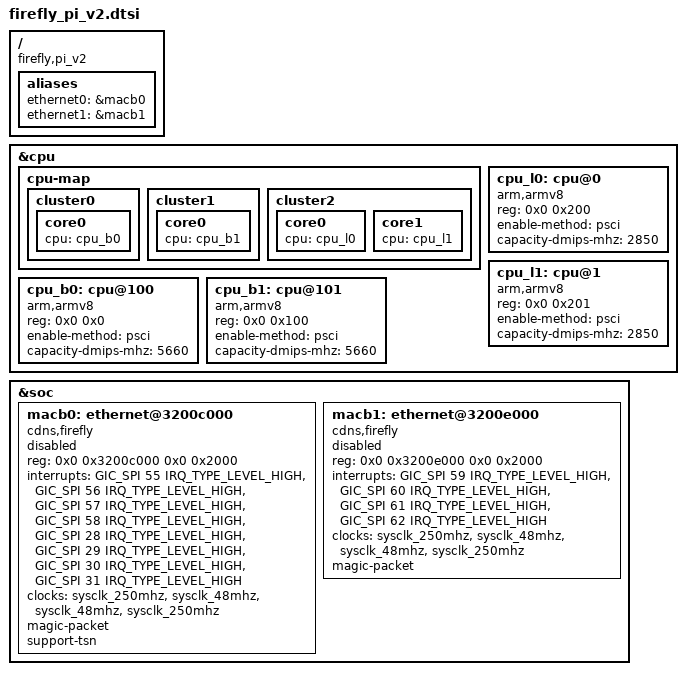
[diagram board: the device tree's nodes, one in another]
#include "firefly_v2.dtsi"

/ {
	compatible = "firefly,pi_v2";

	aliases {
		ethernet0 = &macb0;
		ethernet1 = &macb1;
	};
};

&cpu {
	cpu-map {
		cluster0 {
			core0 {
				cpu = <&cpu_b0>;
			};
		};

		cluster1 {
			core0 {
				cpu = <&cpu_b1>;
			};
		};

		cluster2 {
			core0 {
				cpu = <&cpu_l0>;
			};

			core1 {
				cpu = <&cpu_l1>;
			};
		};
	};

	cpu_l0: cpu@0 {
		device_type = "cpu";
		compatible = "arm,armv8";
		reg = <0x0 0x200>;
		enable-method = "psci";
		capacity-dmips-mhz = <2850>;
	};

	cpu_l1: cpu@1 {
		device_type = "cpu";
		compatible = "arm,armv8";
		reg = <0x0 0x201>;
		enable-method = "psci";
		capacity-dmips-mhz = <2850>;
	};

	cpu_b0: cpu@100 {
		device_type = "cpu";
		compatible = "arm,armv8";
		reg = <0x0 0x0>;
		enable-method = "psci";
		capacity-dmips-mhz = <5660>;
	};

	cpu_b1: cpu@101 {
		device_type = "cpu";
		compatible = "arm,armv8";
		reg = <0x0 0x100>;
		enable-method = "psci";
		capacity-dmips-mhz = <5660>;
	};
};

&soc {
	/*usb3_0: usb3@31a08000 {
		compatible = "generic-xhci";
		reg = <0x0 0x31a08000 0x0 0x18000>;
		interrupts = <GIC_SPI 16 IRQ_TYPE_LEVEL_HIGH>;
		status = "disabled";
	};*/

	macb0: ethernet@3200c000 {
		compatible = "cdns,firefly";
		reg = <0x0 0x3200c000 0x0 0x2000>;
		interrupts = <GIC_SPI 55 IRQ_TYPE_LEVEL_HIGH>,
			     <GIC_SPI 56 IRQ_TYPE_LEVEL_HIGH>,
			     <GIC_SPI 57 IRQ_TYPE_LEVEL_HIGH>,
			     <GIC_SPI 58 IRQ_TYPE_LEVEL_HIGH>,
			     <GIC_SPI 28 IRQ_TYPE_LEVEL_HIGH>,
			     <GIC_SPI 29 IRQ_TYPE_LEVEL_HIGH>,
			     <GIC_SPI 30 IRQ_TYPE_LEVEL_HIGH>,
			     <GIC_SPI 31 IRQ_TYPE_LEVEL_HIGH>;
		clock-names = "pclk", "hclk", "tx_clk", "tsu_clk";
		clocks = <&sysclk_250mhz>, <&sysclk_48mhz>, <&sysclk_48mhz>, <&sysclk_250mhz>;
		magic-packet;
		support-tsn;
		status = "disabled";
	};

	macb1: ethernet@3200e000 {
		compatible = "cdns,firefly";
		reg = <0x0 0x3200e000 0x0 0x2000>;
		interrupts = <GIC_SPI 59 IRQ_TYPE_LEVEL_HIGH>,
			     <GIC_SPI 60 IRQ_TYPE_LEVEL_HIGH>,
			     <GIC_SPI 61 IRQ_TYPE_LEVEL_HIGH>,
			     <GIC_SPI 62 IRQ_TYPE_LEVEL_HIGH>;
		clock-names = "pclk", "hclk", "tx_clk", "tsu_clk";
		clocks = <&sysclk_250mhz>, <&sysclk_48mhz>, <&sysclk_48mhz>, <&sysclk_250mhz>;
		magic-packet;
		status = "disabled";
	};
};
